# RockChip_RK3588 register map
Vendor: RockChip Electronics Co., Ltd.; Series: RK3588; File version: 0.1
Registers are 32-bit, read-write, no defined reset value unless marked. A register's access mark holds for its fields unless they carry their own. Offsets are from the block's base; [hi:lo] are bit positions; {n}, {i} and the like mark numbered series; 'fields as' and 'values as' point back to an identical list; <NAME> marks a mode.

## CRU (part 1 of 6)
Base 0xFD7C0000
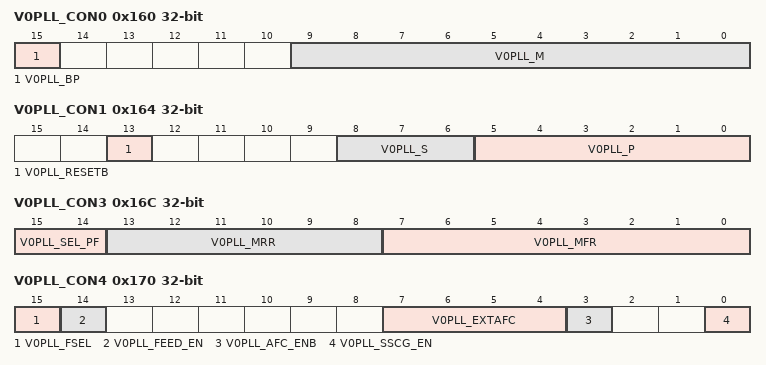
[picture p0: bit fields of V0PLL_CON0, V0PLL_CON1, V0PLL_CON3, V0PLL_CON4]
0x160 V0PLL_CON0 — V0PLL configuration register 0
  [15] V0PLL_BP — BYPASS: Bypass mode control signal.
    0=NORMAL (PLL operates normally.); 1=BYPASS (Bypass mode is enabled. (FOUT = FIN).)
  [9:0] V0PLL_M — M: Division value of the 10-bit programmable main-divider. PLL has to be reset if M value is changed. 64 <= pll_m <= 1023.
0x164 V0PLL_CON1 — V0PLL configuration register 1
  [13] V0PLL_RESETB — RESETB: Power down control signal.
    0=NORMAL (RESETB=0 from 1, PLL starts its normal operation after lock time.); 1=POWER_DOWN (RESETB=1, power down mode is enabled and all digital blocks are reset.)
  [8:6] V0PLL_S — Division value of the 3-bit programmable scaler. 0 <= pll_s <= 6.
  [5:0] V0PLL_P — P: Division value of the 6-bit programmable pre-divider. PLL has to be reset if P value is changed. 1 <= pll_p <= 63.
0x168 V0PLL_CON2 — V0PLL configuration register 2
  [15:0] V0PLL_K — K: Value of 16-bit DSM. pll_k[15:0] is a two's complement integer.
0x16C V0PLL_CON3 — V0PLL configuration register 3
  [15:14] V0PLL_SEL_PF — SEL_PF: Value of 2-bit modulation method control. PLL has to be reset if pll_sel_pf is changed.
    0=DOWN_SPREAD; 1=UP_SPREAD; 2=CENTER_SPREAD_2; 3=CENTER_SPREAD_3
  [13:8] V0PLL_MRR — MRR: Value of 6-bit modulation rate control. PLL has to be reset if pll_mrr is changed.
  [7:0] V0PLL_MFR — MFR: Value of 8-bit modulation frequency control. PLL has to be reset if pll_mfr is changed.
0x170 V0PLL_CON4 — V0PLL configuration register 4
  [15] V0PLL_FSEL — FSEL: Monitoring pin.
    0=FREF (FEED_OUT = FREF.); 1=FEED (FEED_OUT = FEED.)
  [14] V0PLL_FEED_EN — FEED_EN: Monitoring pin.
    0=DISABLED (FEED_OUT is disabled.); 1=ENABLED (FEED_OUT is enabled.)
  [7:4] V0PLL_EXTAFC — EXTAFC: Monitoring pin. If pll_afc_enb=1, AFC is disabled and VCO is calibrated manually by pll_extafc[4:0] for the test of VCO range.
  [3] V0PLL_AFC_ENB — AFC_ENB: Monitoring pin.
    0=ENABLED (AFC is enabled and VCO is calibrated automatically.); 1=DISABLED (AFC is disabled and VCO is calibrated manually by pll_extafc[4:0] for the test of VCO range.)
  [0] V0PLL_SSCG_EN — SSCG_EN: Enable pin for dithered mode.
    0=DISABLE (disable dithered mode.); 1=ENABLE (enable dithered mode.)
0x174 V0PLL_CON5 — V0PLL configuration register 5
  [0] V0PLL_FOUT_MASK — FOUT_MASK: Scaler's re-initialization time control pin.
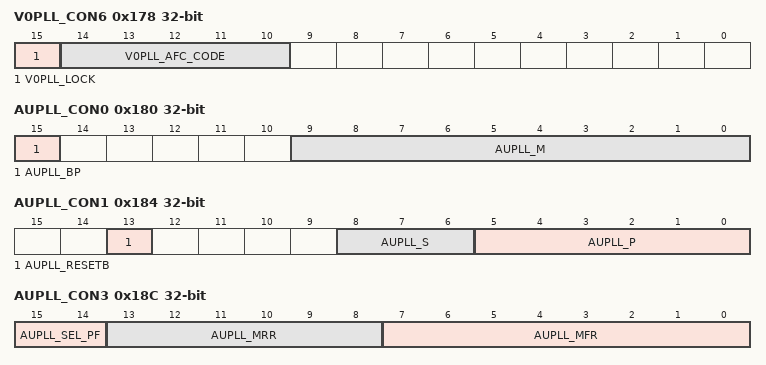
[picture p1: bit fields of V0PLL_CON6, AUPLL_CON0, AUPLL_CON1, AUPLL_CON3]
0x178 V0PLL_CON6 — V0PLL configuration register 6
  [15] V0PLL_LOCK — LOCK: PLL lock flag.
    0=UNLOCKED (PLL is unlocked.); 1=LOCKLED (PLL is locked.)
  [14:10] V0PLL_AFC_CODE — AFC_CODE: Monitoring pin. Output code of AFC(5 bits).
0x180 AUPLL_CON0 — AUPLL configuration register 0
  [15] AUPLL_BP — BYPASS: Bypass mode control signal.
    1=BYPASS (bypass mode is enabled. (FOUT = FIN).); 0=NORMAL (PLL operates normally.)
  [9:0] AUPLL_M — M: Division value of the 10-bit programmable main-divider. PLL has to be reset if M value is changed. 64 <= pll_m <= 1023.
0x184 AUPLL_CON1 — AUPLL configuration register 1
  [13] AUPLL_RESETB — RESETB: Power down control signal.
    values as V0PLL_CON1.V0PLL_RESETB
  [8:6] AUPLL_S — Division value of the 3-bit programmable scaler. 0 <= pll_s <= 6.
  [5:0] AUPLL_P — P: Division value of the 6-bit programmable pre-divider. PLL has to be reset if P value is changed. 1 <= pll_p <= 63.
0x188 AUPLL_CON2 — AUPLL configuration register 2
  [15:0] AUPLL_K — K: Value of 16-bit DSM. pll_k[15:0] is a two's complement integer.
0x18C AUPLL_CON3 — AUPLL configuration register 3
  [15:14] AUPLL_SEL_PF — SEL_PF: Value of 2-bit modulation method control. PLL has to be reset if pll_sel_pf is changed.
    values as V0PLL_CON3.V0PLL_SEL_PF
  [13:8] AUPLL_MRR — MRR: Value of 6-bit modulation rate control. PLL has to be reset if pll_mrr is changed.
  [7:0] AUPLL_MFR — MFR: Value of 8-bit modulation frequency control. PLL has to be reset if pll_mfr is changed.
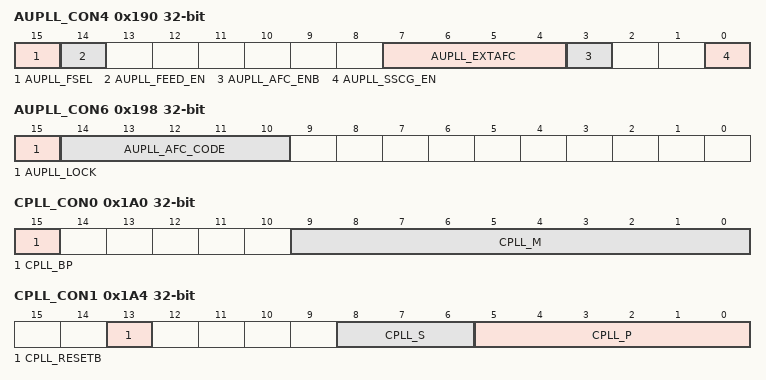
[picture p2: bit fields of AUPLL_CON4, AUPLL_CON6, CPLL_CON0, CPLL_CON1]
0x190 AUPLL_CON4 — AUPLL configuration register 4
  [15] AUPLL_FSEL — FSEL: Monitoring pin.
    0=FREF (FEED_OUT = FREF.); 1=FEED (FEED_OUT = FEED.)
  [14] AUPLL_FEED_EN — FEED_EN: Monitoring pin.
    values as V0PLL_CON4.V0PLL_FEED_EN
  [7:4] AUPLL_EXTAFC — EXTAFC: Monitoring pin. If pll_afc_enb=1, AFC is disabled and VCO is calibrated manually by pll_extafc[4:0] for the test of VCO range.
  [3] AUPLL_AFC_ENB — AFC_ENB: Monitoring pin. pll_extafc[4:0] for the test of VCO range.
    0=ENABLED (AFC is enabled and VCO is calibrated automatically.); 1=DISABLED (AFC is disabled and VCO is calibrated manually by)
  [0] AUPLL_SSCG_EN — SSCG_EN: Enable pin for dithered mode.
    values as V0PLL_CON4.V0PLL_SSCG_EN
0x194 AUPLL_CON5 — AUPLL configuration register 5
  [0] AUPLL_FOUT_MASK — FOUT_MASK: Scaler's re-initialization time control pin.
0x198 AUPLL_CON6 — AUPLL configuration register 6
  [15] AUPLL_LOCK — LOCK: PLL lock flag.
    0=UNLOCKED (PLL is unlocked.); 1=LOCKED (PLL is locked.)
  [14:10] AUPLL_AFC_CODE — AFC_CODE: Monitoring pin. Output code of AFC(5 bits).
0x1A0 CPLL_CON0 — CPLL configuration register 0
  [15] CPLL_BP — BYPASS: Bypass mode control signal.
    values as AUPLL_CON0.AUPLL_BP
  [9:0] CPLL_M — M: Division value of the 10-bit programmable main-divider. PLL has to be reset if M value is changed. 64 <= pll_m <= 1023
0x1A4 CPLL_CON1 — CPLL configuration register 1
  [13] CPLL_RESETB — RESETB: Power down control signal.
    values as V0PLL_CON1.V0PLL_RESETB
  [8:6] CPLL_S — Division value of the 3-bit programmable scaler. 0 <= pll_s <= 6
  [5:0] CPLL_P — P: Division value of the 6-bit programmable pre-divider. PLL has to be reset if P value is changed. 1 <= pll_p <= 63
0x1A8 CPLL_CON2 — CPLL configuration register 2
  [15:0] CPLL_K — K: Value of 16-bit DSM. pll_k[15:0] is a two's complement integer.
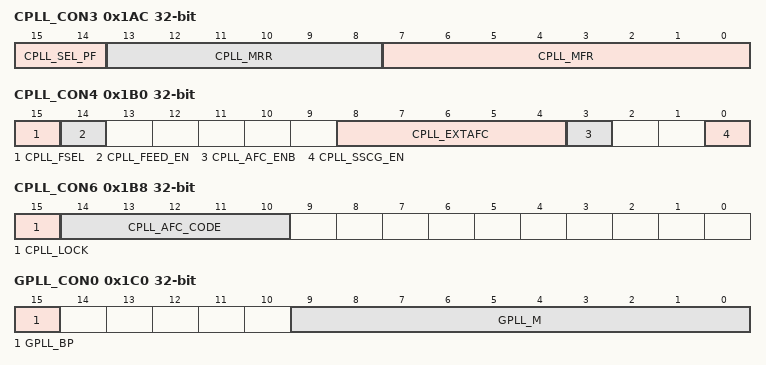
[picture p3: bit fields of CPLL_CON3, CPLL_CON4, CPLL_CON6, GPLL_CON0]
0x1AC CPLL_CON3 — CPLL configuration register 3
  [15:14] CPLL_SEL_PF — SEL_PF: Value of 2-bit modulation method control. PLL has to be reset if pll_sel_pf is changed.
    0=DOWN_SPREAD; 1=UP_SPREAD; 2=CENTER_SPREAD2; 3=CENTER_SPREAD3
  [13:8] CPLL_MRR — MRR: Value of 6-bit modulation rate control. PLL has to be reset if pll_mrr is changed.
  [7:0] CPLL_MFR — MFR: Value of 8-bit modulation frequency control. PLL has to be reset if pll_mfr is changed.
0x1B0 CPLL_CON4 — CPLL configuration register 4
  [15] CPLL_FSEL — FSEL: Monitoring pin.
    0=FREF (FEED_OUT = FREF.); 1=FEED (FEED_OUT = FEED.)
  [14] CPLL_FEED_EN — FEED_EN: Monitoring pin.
    values as V0PLL_CON4.V0PLL_FEED_EN
  [8:4] CPLL_EXTAFC — EXTAFC: Monitoring pin. If pll_afc_enb=1, AFC is disabled and VCO is calibrated manually by pll_extafc[4:0] for the test of VCO range.
  [3] CPLL_AFC_ENB — AFC_ENB: Monitoring pin.
    0=AFC is enabled and VCO is calibrated automatically; 1=AFC is disabled and VCO is calibrated manually by pll_extafc[4:0] for the test of VCO range
  [0] CPLL_SSCG_EN — SSCG_EN: Enable pin for dithered mode.
    values as V0PLL_CON4.V0PLL_SSCG_EN
0x1B4 CPLL_CON5 — CPLL configuration register 5
  [0] CPLL_FOUT_MASK — FOUT_MASK: Scaler's re-initialization time control pin.
0x1B8 CPLL_CON6 — CPLL configuration register 6
  [15] CPLL_LOCK — LOCK: PLL lock flag.
    0=UNLOCKED (PLL is unlocked.); 1=LOCKED (PLL is locked.)
  [14:10] CPLL_AFC_CODE — AFC_CODE: Monitoring pin. Output code of AFC(5 bits).
0x1C0 GPLL_CON0 — GPLL configuration register 0
  [15] GPLL_BP — BYPASS: Bypass mode control signal.
    values as AUPLL_CON0.AUPLL_BP
  [9:0] GPLL_M — M: Division value of the 10-bit programmable main-divider. PLL has to be reset if M value is changed. 64 <= pll_m <= 1023
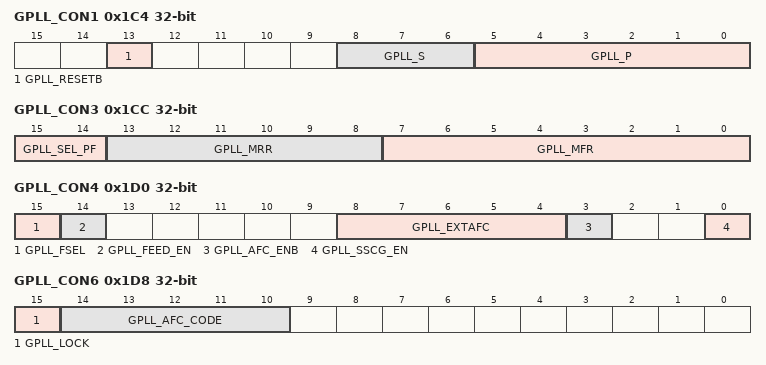
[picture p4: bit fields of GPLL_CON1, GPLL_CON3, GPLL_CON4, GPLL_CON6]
0x1C4 GPLL_CON1 — GPLL configuration register 1
  [13] GPLL_RESETB — RESETB: Power down control signal.
    values as V0PLL_CON1.V0PLL_RESETB
  [8:6] GPLL_S — Division value of the 3-bit programmable scaler. 0 <= pll_s <= 6
  [5:0] GPLL_P — P: Division value of the 6-bit programmable pre-divider. PLL has to be reset if P value is changed. 1 <= pll_p <= 63
0x1C8 GPLL_CON2 — GPLL configuration register 2
  [15:0] GPLL_K — K: Value of 16-bit DSM. pll_k[15:0] is a two's complement integer.
0x1CC GPLL_CON3 — GPLL configuration register 3
  [15:14] GPLL_SEL_PF — SEL_PF: Value of 2-bit modulation method control. PLL has to be reset if pll_sel_pf is changed.
    values as CPLL_CON3.CPLL_SEL_PF
  [13:8] GPLL_MRR — MRR: Value of 6-bit modulation rate control. PLL has to be reset if pll_mrr is changed.
  [7:0] GPLL_MFR — MFR: Value of 8-bit modulation frequency control. PLL has to be reset if pll_mfr is changed.
0x1D0 GPLL_CON4 — GPLL configuration register 4
  [15] GPLL_FSEL — FSEL: Monitoring pin.
    0=FREF (FEED_OUT = FREF.); 1=FEED (FEED_OUT = FEED.)
  [14] GPLL_FEED_EN — FEED_EN: Monitoring pin.
    values as V0PLL_CON4.V0PLL_FEED_EN
  [8:4] GPLL_EXTAFC — EXTAFC: Monitoring pin. If pll_afc_enb=1, AFC is disabled and VCO is calibrated manually by pll_extafc[4:0] for the test of VCO range.
  [3] GPLL_AFC_ENB — AFC_ENB: Monitoring pin.
    values as V0PLL_CON4.V0PLL_AFC_ENB
  [0] GPLL_SSCG_EN — SSCG_EN: Enable pin for dithered mode.
    values as V0PLL_CON4.V0PLL_SSCG_EN
0x1D4 GPLL_CON5 — GPLL configuration register 5
  [0] GPLL_FOUT_MASK — FOUT_MASK: Scaler's re-initialization time control pin.
0x1D8 GPLL_CON6 — GPLL configuration register 6
  [15] GPLL_LOCK — LOCK: PLL lock flag.
    0=UNLOCKED (PLL is unlocked.); 1=LOCKED (PLL is locked.)
  [14:10] GPLL_AFC_CODE — AFC_CODE: Monitoring pin. Output code of AFC(5 bits).
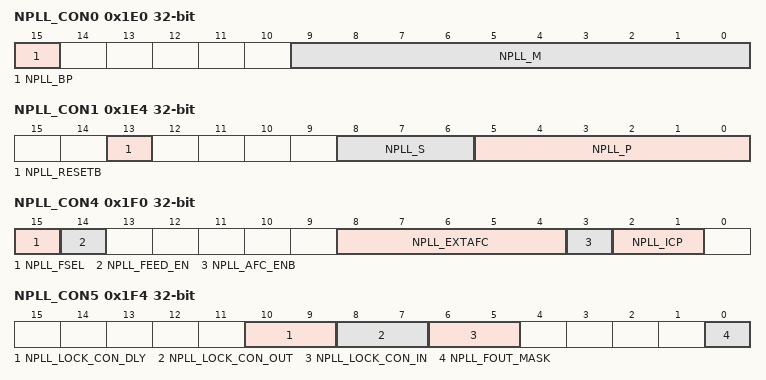
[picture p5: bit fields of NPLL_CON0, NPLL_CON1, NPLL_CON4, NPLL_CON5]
0x1E0 NPLL_CON0 — Internal PLL mode select register 0
  [15] NPLL_BP — BYPASS: Bypass mode control signal.
    values as AUPLL_CON0.AUPLL_BP
  [9:0] NPLL_M — M: Division value of the 10-bit programmable main-divider. PLL has to be reset if M value is changed. 64 <= pll_m <= 1023
0x1E4 NPLL_CON1 — Internal PLL mode select register 1
  [13] NPLL_RESETB — RESETB: Power down control signal.
    values as V0PLL_CON1.V0PLL_RESETB
  [8:6] NPLL_S — Division value of the 3-bit programmable scaler. 0 <= pll_s <= 6
  [5:0] NPLL_P — P: Division value of the 6-bit programmable pre-divider. PLL has to be reset if P value is changed. 1 <= pll_p <= 63
0x1F0 NPLL_CON4 — Internal PLL mode select register 4
  [15] NPLL_FSEL — FSEL: Monitoring pin.
    0=FREF (FEED_OUT = FREF.); 1=FEED (FEED_OUT = FEED.)
  [14] NPLL_FEED_EN — FEED_EN: Monitoring pin.
    values as V0PLL_CON4.V0PLL_FEED_EN
  [8:4] NPLL_EXTAFC — EXTAFC: Monitoring pin. If pll_afc_enb=1, AFC is disabled and VCO is calibrated manually by pll_extafc[4:0] for the test of VCO range.
  [3] NPLL_AFC_ENB — AFC_ENB: Monitoring pin.
    values as V0PLL_CON4.V0PLL_AFC_ENB
  [2:1] NPLL_ICP — Charge-pump current control signal.
0x1F4 NPLL_CON5 — Internal PLL mode select register 5
  [10:9] NPLL_LOCK_CON_DLY — LOCK_CON_DLY: Lock detector setting of the detection resolution.
  [8:7] NPLL_LOCK_CON_OUT — LOCK_CON_OUT: Lock detector setting of the output margin.
  [6:5] NPLL_LOCK_CON_IN — LOCK_CON_IN: Lock detector setting of the input margin.
  [0] NPLL_FOUT_MASK — FOUT_MASK: Scaler's re-initialization time control pin.
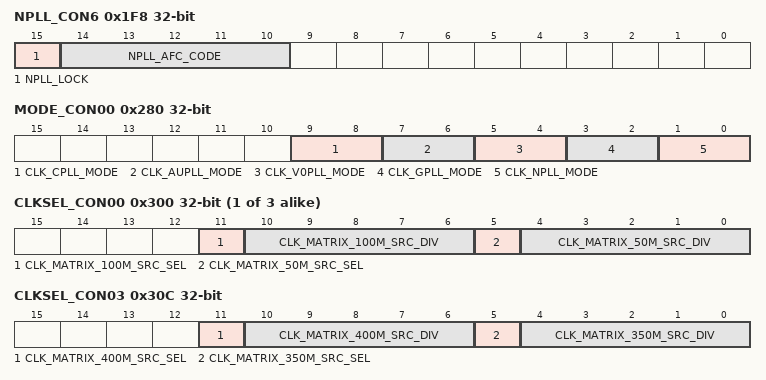
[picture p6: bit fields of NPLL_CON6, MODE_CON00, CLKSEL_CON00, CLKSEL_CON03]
0x1F8 NPLL_CON6 — Internal PLL mode select register 6
  [15] NPLL_LOCK — LOCK: PLL lock flag.
    0=UNLOCKED (PLL is unlocked.); 1=LOCKED (PLL is locked.)
  [14:10] NPLL_AFC_CODE — AFC_CODE: Monitoring pin. Output code of AFC(5 bits).
0x280 MODE_CON00 — Internal PLL mode select register
  [9:8] CLK_CPLL_MODE — clk_cpll_mux clock mux.
    0=XIN_OSC0_FUNC; 1=CLK_CPLL; 2=CLK_DEEPSLOW
  [7:6] CLK_AUPLL_MODE — clk_aupll_mux clock mux.
    0=XIN_OSC0_FUNC; 1=CLK_AUPLL; 2=CLK_DEEPSLOW
  [5:4] CLK_V0PLL_MODE — clk_v0pll_mux clock mux.
    0=XIN_OSC0_FUNC; 1=CLK_V0PLL; 2=CLK_DEEPSLOW
  [3:2] CLK_GPLL_MODE — clk_gpll_mux clock mux.
    0=XIN_OSC0_FUNC; 1=CLK_GPLL; 2=CLK_DEEPSLOW
  [1:0] CLK_NPLL_MODE — clk_npll_mux clock mux.
    0=XIN_OSC0_FUNC; 1=CLK_NPLL; 2=CLK_DEEPSLOW
{0x300+4i} CLKSEL_CON{i:02} (i=0..2) — Internal clock select and division register {i}
  [11] CLK_MATRIX_{100i+100}M_SRC_SEL — clk_matrix_{100i+100}m_src clock mux.
    0=CLK_GPLL_MUX; 1=CLK_CPLL_MUX
  [10:6] CLK_MATRIX_{100i+100}M_SRC_DIV — Divide clk_matrix_{100i+100}m_src by (div_con + 1).
  [5] CLK_MATRIX_{100i+50}M_SRC_SEL — clk_matrix_{100i+50}m_src clock mux.
    0=CLK_GPLL_MUX; 1=CLK_CPLL_MUX
  [4:0] CLK_MATRIX_{100i+50}M_SRC_DIV — Divide clk_matrix_{100i+50}m_src by (div_con + 1).
0x30C CLKSEL_CON03 — Internal clock select and division register 3
  [11] CLK_MATRIX_400M_SRC_SEL — clk_matrix_400m_src clock mux.
    0=CLK_GPLL_MUX; 1=CLK_CPLL_MUX
  [10:6] CLK_MATRIX_400M_SRC_DIV — Divide clk_matrix_400m_src by (div_con + 1).
  [5] CLK_MATRIX_350M_SRC_SEL — clk_matrix_350m_src clock mux.
    0=CLK_GPLL_MUX; 1=CLK_SPLL_MUX
  [4:0] CLK_MATRIX_350M_SRC_DIV — Divide clk_matrix_350m_src by (div_con + 1).
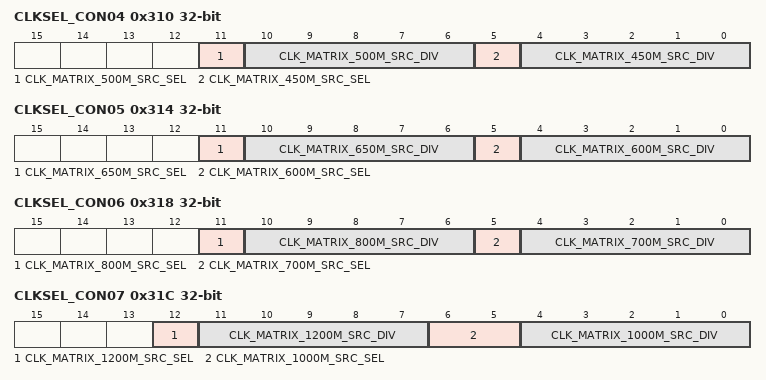
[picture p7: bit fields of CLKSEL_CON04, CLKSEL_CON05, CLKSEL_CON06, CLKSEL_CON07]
0x310 CLKSEL_CON04 — Internal clock select and division register 4
  [11] CLK_MATRIX_500M_SRC_SEL — clk_matrix_500m_src clock mux.
    0=CLK_GPLL_MUX; 1=CLK_CPLL_MUX
  [10:6] CLK_MATRIX_500M_SRC_DIV — Divide clk_matrix_500m_src by (div_con + 1).
  [5] CLK_MATRIX_450M_SRC_SEL — clk_matrix_450m_src clock mux.
    0=CLK_GPLL_MUX; 1=CLK_CPLL_MUX
  [4:0] CLK_MATRIX_450M_SRC_DIV — NP5 division register. Divide clk_matrix_450m_src by ((2 * div_con + 3) / 2).
0x314 CLKSEL_CON05 — Internal clock select and division register 5
  [11] CLK_MATRIX_650M_SRC_SEL — clk_matrix_650m_src clock mux.
    0=CLK_GPLL_MUX; 1=CLK_LPLL_MUX
  [10:6] CLK_MATRIX_650M_SRC_DIV — Divide clk_matrix_650m_src by (div_con + 1).
  [5] CLK_MATRIX_600M_SRC_SEL — clk_matrix_600m_src clock mux.
    0=CLK_GPLL_MUX; 1=CLK_CPLL_MUX
  [4:0] CLK_MATRIX_600M_SRC_DIV — Divide clk_matrix_600m_src by (div_con + 1).
0x318 CLKSEL_CON06 — Internal clock select and division register 6
  [11] CLK_MATRIX_800M_SRC_SEL — clk_matrix_800m_src clock mux.
    0=CLK_GPLL_MUX; 1=CLK_AUPLL_MUX
  [10:6] CLK_MATRIX_800M_SRC_DIV — Divide clk_matrix_800m_src by (div_con + 1).
  [5] CLK_MATRIX_700M_SRC_SEL — clk_matrix_700m_src clock mux.
    0=CLK_GPLL_MUX; 1=CLK_SPLL_MUX
  [4:0] CLK_MATRIX_700M_SRC_DIV — Divide clk_matrix_700m_src by (div_con + 1).
0x31C CLKSEL_CON07 — Internal clock select and division register 7
  [12] CLK_MATRIX_1200M_SRC_SEL — clk_matrix_1200m_src clock mux.
    0=CLK_GPLL_MUX; 1=CLK_CPLL_MUX
  [11:7] CLK_MATRIX_1200M_SRC_DIV — Divide clk_matrix_1200m_src by (div_con + 1).
  [6:5] CLK_MATRIX_1000M_SRC_SEL — clk_matrix_1000m_src clock mux.
    0=CLK_GPLL_MUX; 1=CLK_CPLL_MUX; 2=CLK_NPLL_MUX; 3=CLK_V0PLL_MUX
  [4:0] CLK_MATRIX_1000M_SRC_DIV — NP5 division register. Divide clk_matrix_1000m_src by ((2 * div_con + 3) / 2).
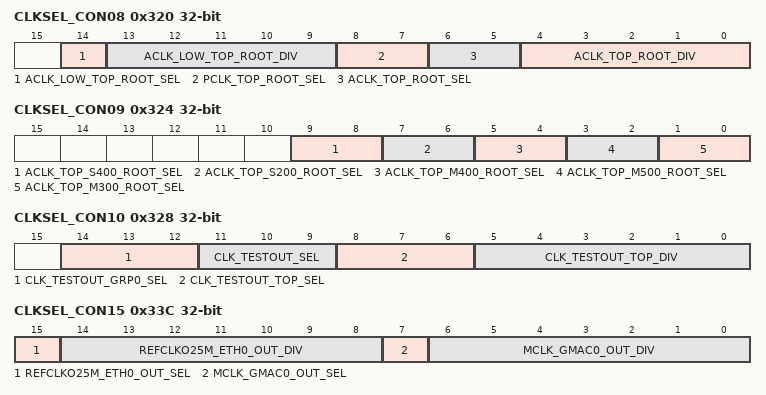
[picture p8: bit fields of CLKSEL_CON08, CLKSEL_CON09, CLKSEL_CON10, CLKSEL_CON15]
0x320 CLKSEL_CON08 — Internal clock select and division register 8
  [14] ACLK_LOW_TOP_ROOT_SEL — aclk_low_top_root clock mux.
    0=CLK_GPLL_MUX; 1=CLK_CPLL_MUX
  [13:9] ACLK_LOW_TOP_ROOT_DIV — Divide aclk_low_top_root by (div_con + 1).
  [8:7] PCLK_TOP_ROOT_SEL — pclk_top_root clock mux.
    0=CLK_MATRIX_100M_SRC; 1=CLK_MATRIX_50M_SRC; 2=XIN_OSC0_FUNC
  [6:5] ACLK_TOP_ROOT_SEL — aclk_top_root clock mux.
    0=CLK_GPLL_MUX; 1=CLK_CPLL_MUX; 2=CLK_AUPLL_MUX
  [4:0] ACLK_TOP_ROOT_DIV — Divide aclk_top_root by (div_con + 1).
0x324 CLKSEL_CON09 — Internal clock select and division register 9
  [9:8] ACLK_TOP_S400_ROOT_SEL — aclk_top_s400_root clock mux.
    0=CLK_MATRIX_400M_SRC; 1=CLK_MATRIX_200M_SRC; 2=CLK_MATRIX_100M_SRC; 3=XIN_OSC0_FUNC
  [7:6] ACLK_TOP_S200_ROOT_SEL — aclk_top_s200_root clock mux.
    0=CLK_MATRIX_200M_SRC; 1=CLK_MATRIX_100M_SRC; 2=CLK_MATRIX_50M_SRC; 3=XIN_OSC0_FUNC
  [5:4] ACLK_TOP_M400_ROOT_SEL — aclk_top_m400_root clock mux.
    values as ACLK_TOP_S400_ROOT_SEL
  [3:2] ACLK_TOP_M500_ROOT_SEL — aclk_top_m500_root clock mux.
    0=CLK_MATRIX_500M_SRC; 1=CLK_MATRIX_300M_SRC; 2=CLK_MATRIX_100M_SRC; 3=XIN_OSC0_FUNC
  [1:0] ACLK_TOP_M300_ROOT_SEL — aclk_top_m300_root clock mux.
    0=CLK_MATRIX_300M_SRC; 1=CLK_MATRIX_200M_SRC; 2=CLK_MATRIX_100M_SRC; 3=XIN_OSC0_FUNC
0x328 CLKSEL_CON10 — Internal clock select and division register 10
  [14:12] CLK_TESTOUT_GRP0_SEL — clk_testout_grp0 clock mux.
    0=CLK_REF_PIPE_PHY0; 1=CLK_REF_PIPE_PHY1; 2=CLK_REF_PIPE_PHY2; 3=CLK_TESTOUT_TOP; 4=CLK_TESTOUT_GPU; 5=CLK_TESTOUT_NPU
  [11:9] CLK_TESTOUT_SEL — clk_testout clock mux.
    0=CLK_TESTOUT_GRP0; 1=CLK_TESTOUT_B0; 2=CLK_TESTOUT_B1; 3=CLK_TESTOUT_L; 4=CLK_TESTOUT_DDR01; 5=CLK_TESTOUT_DDR23
  [8:6] CLK_TESTOUT_TOP_SEL — clk_testout_top clock mux.
    0=CLK_GPLL_MUX; 1=CLK_CPLL_MUX; 2=CLK_AUPLL_MUX; 3=CLK_SPLL_MUX; 4=CLK_V0PLL_MUX; 5=CLK_DEEPSLOW
  [5:0] CLK_TESTOUT_TOP_DIV — Divide clk_testout_top by (div_con + 1).
0x33C CLKSEL_CON15 — Internal clock select and division register 15
  [15] REFCLKO25M_ETH0_OUT_SEL — refclko25m_eth0_out clock mux.
    0=CLK_GPLL_MUX; 1=CLK_CPLL_MUX
  [14:8] REFCLKO25M_ETH0_OUT_DIV — Divide refclko25m_eth0_out by (div_con + 1).
  [7] MCLK_GMAC0_OUT_SEL — mclk_gmac0_out clock mux.
    0=CLK_GPLL_MUX; 1=CLK_CPLL_MUX
  [6:0] MCLK_GMAC0_OUT_DIV — Divide mclk_gmac0_out by (div_con + 1).
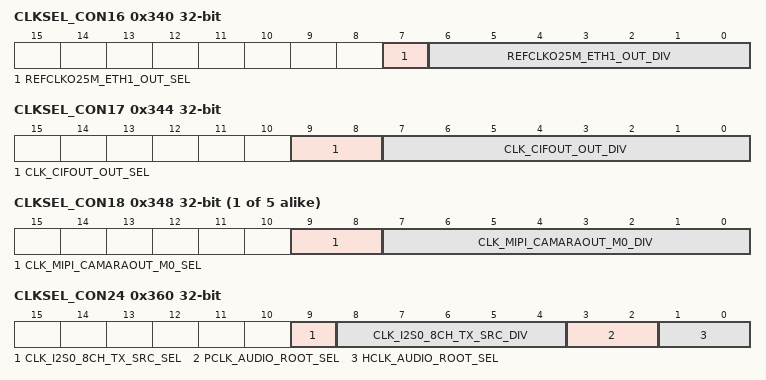
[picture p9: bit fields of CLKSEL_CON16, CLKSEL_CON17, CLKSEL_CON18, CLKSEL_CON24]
0x340 CLKSEL_CON16 — Internal clock select and division register 16
  [7] REFCLKO25M_ETH1_OUT_SEL — refclko25m_eth1_out clock mux.
    0=CLK_GPLL_MUX; 1=CLK_CPLL_MUX
  [6:0] REFCLKO25M_ETH1_OUT_DIV — Divide refclko25m_eth1_out by (div_con + 1).
0x344 CLKSEL_CON17 — Internal clock select and division register 17
  [9:8] CLK_CIFOUT_OUT_SEL — clk_cifout_out clock mux.
    0=CLK_GPLL_MUX; 1=CLK_CPLL_MUX; 2=XIN_OSC0_FUNC; 3=CLK_SPLL_MUX
  [7:0] CLK_CIFOUT_OUT_DIV — Divide clk_cifout_out by (div_con + 1).
{0x300+4i} CLKSEL_CON{i} (i=18..22) — Internal clock select and division register {i}
  [9:8] CLK_MIPI_CAMARAOUT_M{i-18}_SEL — clk_mipi_camaraout_m{i-18} clock mux.
    0=XIN_OSC0_FUNC; 1=CLK_SPLL_MUX; 2=CLK_GPLL_MUX; 3=CLK_CPLL_MUX
  [7:0] CLK_MIPI_CAMARAOUT_M{i-18}_DIV — Divide clk_mipi_camaraout_m{i-18} by (div_con + 1).
0x360 CLKSEL_CON24 — Internal clock select and division register 24
  [9] CLK_I2S0_8CH_TX_SRC_SEL — clk_i2s0_8ch_tx_src clock mux.
    0=CLK_GPLL_MUX; 1=CLK_AUPLL_MUX
  [8:4] CLK_I2S0_8CH_TX_SRC_DIV — Divide clk_i2s0_8ch_tx_src by (div_con + 1).
  [3:2] PCLK_AUDIO_ROOT_SEL — pclk_audio_root clock mux.
    0=CLK_MATRIX_100M_SRC; 1=CLK_MATRIX_50M_SRC; 2=XIN_OSC0_FUNC
  [1:0] HCLK_AUDIO_ROOT_SEL — hclk_audio_root clock mux.
    values as CLKSEL_CON09.ACLK_TOP_S200_ROOT_SEL
0x364 CLKSEL_CON25 — Internal clock select and division register 25
  [31:0] CLK_I2S0_8CH_TX_FRAC_DIV — clk_i2s0_8ch_tx_frac fraction division register. High 16-bit for numerator Low 16-bit for denominator
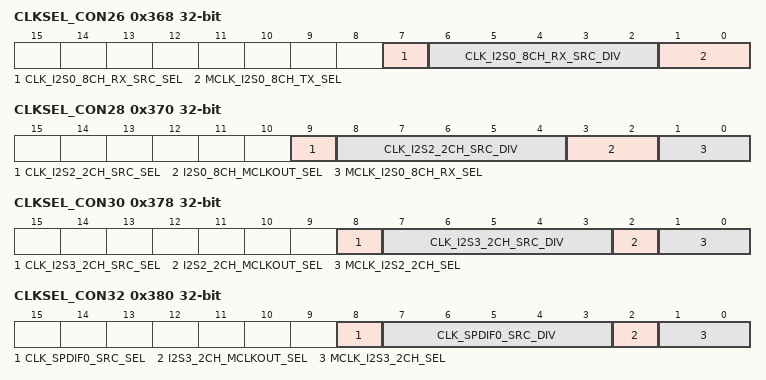
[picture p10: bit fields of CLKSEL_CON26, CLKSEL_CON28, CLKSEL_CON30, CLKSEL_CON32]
0x368 CLKSEL_CON26 — Internal clock select and division register 26
  [7] CLK_I2S0_8CH_RX_SRC_SEL — clk_i2s0_8ch_rx_src clock mux.
    0=CLK_GPLL_MUX; 1=CLK_AUPLL_MUX
  [6:2] CLK_I2S0_8CH_RX_SRC_DIV — Divide clk_i2s0_8ch_rx_src by (div_con + 1).
  [1:0] MCLK_I2S0_8CH_TX_SEL — mclk_i2s0_8ch_tx clock mux.
    0=CLK_I2S0_8CH_TX_SRC; 1=CLK_I2S0_8CH_TX_FRAC; 2=I2S0_MCLKIN; 3=XIN_OSC0_HALF
0x36C CLKSEL_CON27 — Internal clock select and division register 27
  [31:0] CLK_I2S0_8CH_RX_FRAC_DIV — clk_i2s0_8ch_rx_frac fraction division register. High 16-bit for numerator Low 16-bit for denominator
0x370 CLKSEL_CON28 — Internal clock select and division register 28
  [9] CLK_I2S2_2CH_SRC_SEL — clk_i2s2_2ch_src clock mux.
    0=CLK_GPLL_MUX; 1=CLK_AUPLL_MUX
  [8:4] CLK_I2S2_2CH_SRC_DIV — Divide clk_i2s2_2ch_src by (div_con + 1).
  [3:2] I2S0_8CH_MCLKOUT_SEL — i2s0_8ch_mclkout clock mux.
    0=MCLK_I2S0_8CH_TX; 1=MCLK_I2S0_8CH_RX; 2=XIN_OSC0_HALF
  [1:0] MCLK_I2S0_8CH_RX_SEL — mclk_i2s0_8ch_rx clock mux.
    0=CLK_I2S0_8CH_RX_SRC; 1=CLK_I2S0_8CH_RX_FRAC; 2=I2S0_MCLKIN; 3=XIN_OSC0_HALF
0x374 CLKSEL_CON29 — Internal clock select and division register 29
  [31:0] CLK_I2S2_2CH_FRAC_DIV — clk_i2s2_2ch_frac fraction division register. High 16-bit for numerator Low 16-bit for denominator
0x378 CLKSEL_CON30 — Internal clock select and division register 30
  [8] CLK_I2S3_2CH_SRC_SEL — clk_i2s3_2ch_src clock mux.
    0=CLK_GPLL_MUX; 1=CLK_AUPLL_MUX
  [7:3] CLK_I2S3_2CH_SRC_DIV — Divide clk_i2s3_2ch_src by (div_con + 1).
  [2] I2S2_2CH_MCLKOUT_SEL — i2s2_2ch_mclkout clock mux.
    0=MCLK_I2S2_2CH; 1=XIN_OSC0_HALF
  [1:0] MCLK_I2S2_2CH_SEL — mclk_i2s2_2ch clock mux.
    0=CLK_I2S2_2CH_SRC; 1=CLK_I2S2_2CH_FRAC; 2=I2S2_MCLKIN; 3=XIN_OSC0_HALF
0x37C CLKSEL_CON31 — Internal clock select and division register 31
  [31:0] CLK_I2S3_2CH_FRAC_DIV — clk_i2s3_2ch_frac fraction division register. High 16-bit for numerator Low 16-bit for denominator
0x380 CLKSEL_CON32 — Internal clock select and division register 32
  [8] CLK_SPDIF0_SRC_SEL — clk_spdif0_src clock mux.
    0=CLK_GPLL_MUX; 1=CLK_AUPLL_MUX
  [7:3] CLK_SPDIF0_SRC_DIV — Divide clk_spdif0_src by (div_con + 1).
  [2] I2S3_2CH_MCLKOUT_SEL — i2s3_2ch_mclkout clock mux.
    0=MCLK_I2S3_2CH; 1=XIN_OSC0_HALF
  [1:0] MCLK_I2S3_2CH_SEL — mclk_i2s3_2ch clock mux.
    0=CLK_I2S3_2CH_SRC; 1=CLK_I2S3_2CH_FRAC; 2=I2S3_MCLKIN; 3=XIN_OSC0_HALF
0x384 CLKSEL_CON33 — Internal clock select and division register 33
  [31:0] CLK_SPDIF0_FRAC_DIV — clk_spdif0_frac fraction division register. High 16-bit for numerator Low 16-bit for denominator
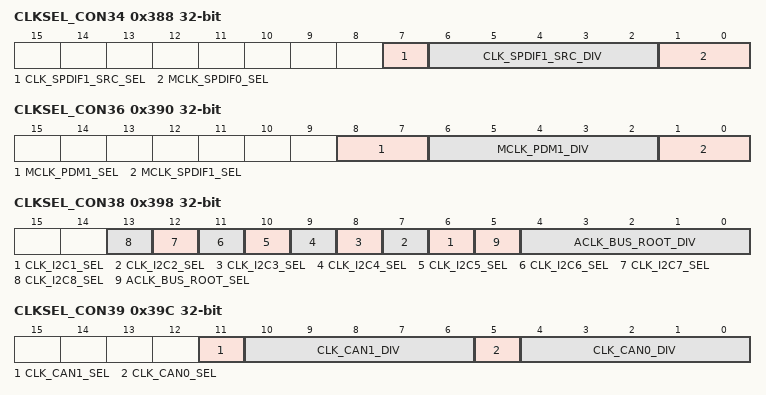
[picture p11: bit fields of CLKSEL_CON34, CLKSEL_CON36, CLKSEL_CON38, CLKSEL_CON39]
0x388 CLKSEL_CON34 — Internal clock select and division register 34
  [7] CLK_SPDIF1_SRC_SEL — clk_spdif1_src clock mux.
    0=CLK_GPLL_MUX; 1=CLK_AUPLL_MUX
  [6:2] CLK_SPDIF1_SRC_DIV — Divide clk_spdif1_src by (div_con + 1).
  [1:0] MCLK_SPDIF0_SEL — mclk_spdif0 clock mux.
    0=CLK_SPDIF0_SRC; 1=CLK_SPDIF0_FRAC; 2=XIN_OSC0_HALF
0x38C CLKSEL_CON35 — Internal clock select and division register 35
  [31:0] CLK_SPDIF1_FRAC_DIV — clk_spdif1_frac fraction division register. High 16-bit for numerator Low 16-bit for denominator
0x390 CLKSEL_CON36 — Internal clock select and division register 36
  [8:7] MCLK_PDM1_SEL — mclk_pdm1 clock mux.
    0=CLK_GPLL_MUX; 1=CLK_CPLL_MUX; 2=CLK_AUPLL_MUX
  [6:2] MCLK_PDM1_DIV — Divide mclk_pdm1 by (div_con + 1).
  [1:0] MCLK_SPDIF1_SEL — mclk_spdif1 clock mux.
    0=CLK_SPDIF1_SRC; 1=CLK_SPDIF1_FRAC; 2=XIN_OSC0_HALF
0x398 CLKSEL_CON38 — Internal clock select and division register 38
  [n+5] CLK_I2C{n}_SEL (n=1..8) — clk_i2c{n} clock mux.
    0=CLK_MATRIX_200M_SRC; 1=CLK_MATRIX_100M_SRC
  [5] ACLK_BUS_ROOT_SEL — aclk_bus_root clock mux.
    0=CLK_GPLL_MUX; 1=CLK_CPLL_MUX
  [4:0] ACLK_BUS_ROOT_DIV — Divide aclk_bus_root by (div_con + 1).
0x39C CLKSEL_CON39 — Internal clock select and division register 39
  [11] CLK_CAN1_SEL — clk_can1 clock mux.
    0=CLK_GPLL_MUX; 1=CLK_CPLL_MUX
  [10:6] CLK_CAN1_DIV — Divide clk_can1 by (div_con + 1).
  [5] CLK_CAN0_SEL — clk_can0 clock mux.
    0=CLK_GPLL_MUX; 1=CLK_CPLL_MUX
  [4:0] CLK_CAN0_DIV — Divide clk_can0 by (div_con + 1).
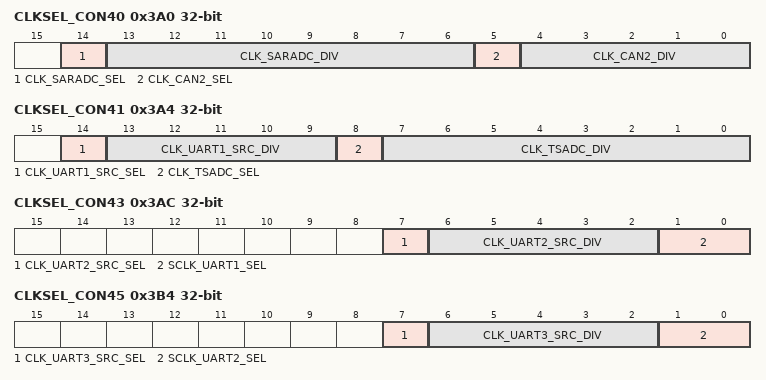
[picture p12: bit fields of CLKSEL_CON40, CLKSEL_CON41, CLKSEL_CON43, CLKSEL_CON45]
0x3A0 CLKSEL_CON40 — Internal clock select and division register 40
  [14] CLK_SARADC_SEL — clk_saradc clock mux.
    0=CLK_GPLL_MUX; 1=XIN_OSC0_FUNC
  [13:6] CLK_SARADC_DIV — Divide clk_saradc by (div_con + 1).
  [5] CLK_CAN2_SEL — clk_can2 clock mux.
    0=CLK_GPLL_MUX; 1=CLK_CPLL_MUX
  [4:0] CLK_CAN2_DIV — Divide clk_can2 by (div_con + 1).
0x3A4 CLKSEL_CON41 — Internal clock select and division register 41
  [14] CLK_UART1_SRC_SEL — clk_uart1_src clock mux.
    0=CLK_GPLL_MUX; 1=CLK_CPLL_MUX
  [13:9] CLK_UART1_SRC_DIV — Divide clk_uart1_src by (div_con + 1).
  [8] CLK_TSADC_SEL — clk_tsadc clock mux.
    0=CLK_GPLL_MUX; 1=XIN_OSC0_FUNC
  [7:0] CLK_TSADC_DIV — Divide clk_tsadc by (div_con + 1).
0x3A8 CLKSEL_CON42 — Internal clock select and division register 42
  [31:0] CLK_UART1_FRAC_DIV — clk_uart1_frac fraction division register. High 16-bit for numerator Low 16-bit for denominator
0x3AC CLKSEL_CON43 — Internal clock select and division register 43
  [7] CLK_UART2_SRC_SEL — clk_uart2_src clock mux.
    0=CLK_GPLL_MUX; 1=CLK_CPLL_MUX
  [6:2] CLK_UART2_SRC_DIV — Divide clk_uart2_src by (div_con + 1).
  [1:0] SCLK_UART1_SEL — sclk_uart1 clock mux.
    0=CLK_UART1_SRC; 1=CLK_UART1_FRAC; 2=XIN_OSC0_FUNC
0x3B0 CLKSEL_CON44 — Internal clock select and division register 44
  [31:0] CLK_UART2_FRAC_DIV — clk_uart2_frac fraction division register. High 16-bit for numerator Low 16-bit for denominator
0x3B4 CLKSEL_CON45 — Internal clock select and division register 45
  [7] CLK_UART3_SRC_SEL — clk_uart3_src clock mux.
    0=CLK_GPLL_MUX; 1=CLK_CPLL_MUX
  [6:2] CLK_UART3_SRC_DIV — Divide clk_uart3_src by (div_con + 1).
  [1:0] SCLK_UART2_SEL — sclk_uart2 clock mux.
    0=CLK_UART2_SRC; 1=CLK_UART2_FRAC; 2=XIN_OSC0_FUNC
0x3B8 CLKSEL_CON46 — Internal clock select and division register 46
  [31:0] CLK_UART3_FRAC_DIV — clk_uart3_frac fraction division register. High 16-bit for numerator Low 16-bit for denominator
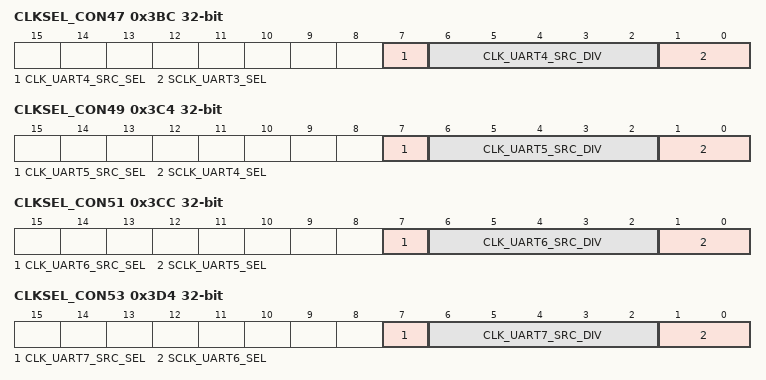
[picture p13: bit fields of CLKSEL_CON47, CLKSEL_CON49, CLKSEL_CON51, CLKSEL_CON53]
0x3BC CLKSEL_CON47 — Internal clock select and division register 47
  [7] CLK_UART4_SRC_SEL — clk_uart4_src clock mux.
    0=CLK_GPLL_MUX; 1=CLK_CPLL_MUX
  [6:2] CLK_UART4_SRC_DIV — Divide clk_uart4_src by (div_con + 1).
  [1:0] SCLK_UART3_SEL — sclk_uart3 clock mux.
    0=CLK_UART3_SRC; 1=CLK_UART3_FRAC; 2=XIN_OSC0_FUNC
0x3C0 CLKSEL_CON48 — Internal clock select and division register 48
  [31:0] CLK_UART4_FRAC_DIV — clk_uart4_frac fraction division register. High 16-bit for numerator Low 16-bit for denominator
0x3C4 CLKSEL_CON49 — Internal clock select and division register 49
  [7] CLK_UART5_SRC_SEL — clk_uart5_src clock mux.
    0=CLK_GPLL_MUX; 1=CLK_CPLL_MUX
  [6:2] CLK_UART5_SRC_DIV — Divide clk_uart5_src by (div_con + 1).
  [1:0] SCLK_UART4_SEL — sclk_uart4 clock mux.
    0=CLK_UART4_SRC; 1=CLK_UART4_FRAC; 2=XIN_OSC0_FUNC
0x3C8 CLKSEL_CON50 — Internal clock select and division register 50
  [31:0] CLK_UART5_FRAC_DIV — clk_uart5_frac fraction division register. High 16-bit for numerator Low 16-bit for denominator
0x3CC CLKSEL_CON51 — Internal clock select and division register 51
  [7] CLK_UART6_SRC_SEL — clk_uart6_src clock mux.
    0=CLK_GPLL_MUX; 1=CLK_CPLL_MUX
  [6:2] CLK_UART6_SRC_DIV — Divide clk_uart6_src by (div_con + 1).
  [1:0] SCLK_UART5_SEL — sclk_uart5 clock mux.
    0=CLK_UART5_SRC; 1=CLK_UART5_FRAC; 2=XIN_OSC0_FUNC
0x3D0 CLKSEL_CON52 — Internal clock select and division register 52
  [31:0] CLK_UART6_FRAC_DIV — clk_uart6_frac fraction division register. High 16-bit for numerator Low 16-bit for denominator
0x3D4 CLKSEL_CON53 — Internal clock select and division register 53
  [7] CLK_UART7_SRC_SEL — clk_uart7_src clock mux.
    0=CLK_GPLL_MUX; 1=CLK_CPLL_MUX
  [6:2] CLK_UART7_SRC_DIV — Divide clk_uart7_src by (div_con + 1).
  [1:0] SCLK_UART6_SEL — sclk_uart6 clock mux.
    0=CLK_UART6_SRC; 1=CLK_UART6_FRAC; 2=XIN_OSC0_FUNC
0x3D8 CLKSEL_CON54 — Internal clock select and division register 54
  [31:0] CLK_UART7_FRAC_DIV — clk_uart7_frac fraction division register. High 16-bit for numerator Low 16-bit for denominator
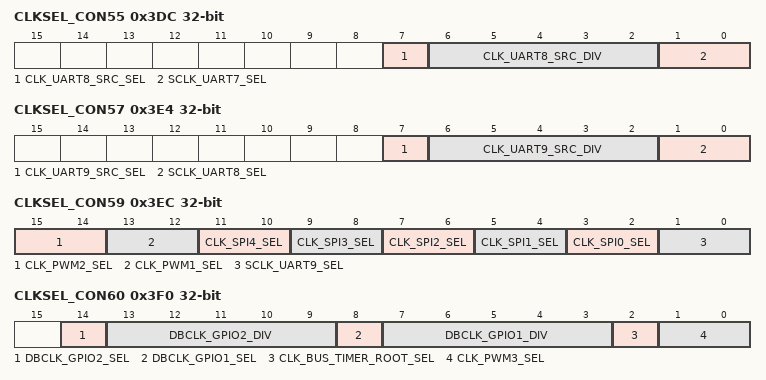
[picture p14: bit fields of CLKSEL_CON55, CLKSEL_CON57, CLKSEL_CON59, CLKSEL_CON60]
0x3DC CLKSEL_CON55 — Internal clock select and division register 55
  [7] CLK_UART8_SRC_SEL — clk_uart8_src clock mux.
    0=CLK_GPLL_MUX; 1=CLK_CPLL_MUX
  [6:2] CLK_UART8_SRC_DIV — Divide clk_uart8_src by (div_con + 1).
  [1:0] SCLK_UART7_SEL — sclk_uart7 clock mux.
    0=CLK_UART7_SRC; 1=CLK_UART7_FRAC; 2=XIN_OSC0_FUNC
0x3E0 CLKSEL_CON56 — Internal clock select and division register 56
  [31:0] CLK_UART8_FRAC_DIV — clk_uart8_frac fraction division register. High 16-bit for numerator Low 16-bit for denominator
0x3E4 CLKSEL_CON57 — Internal clock select and division register 57
  [7] CLK_UART9_SRC_SEL — clk_uart9_src clock mux.
    0=CLK_GPLL_MUX; 1=CLK_CPLL_MUX
  [6:2] CLK_UART9_SRC_DIV — Divide clk_uart9_src by (div_con + 1).
  [1:0] SCLK_UART8_SEL — sclk_uart8 clock mux.
    0=CLK_UART8_SRC; 1=CLK_UART8_FRAC; 2=XIN_OSC0_FUNC
0x3E8 CLKSEL_CON58 — Internal clock select and division register 58
  [31:0] CLK_UART9_FRAC_DIV — clk_uart9_frac fraction division register. High 16-bit for numerator Low 16-bit for denominator
0x3EC CLKSEL_CON59 — Internal clock select and division register 59
  [15:14] CLK_PWM2_SEL — clk_pwm2 clock mux.
    0=CLK_MATRIX_100M_SRC; 1=CLK_MATRIX_50M_SRC; 2=XIN_OSC0_FUNC
  [13:12] CLK_PWM1_SEL — clk_pwm1 clock mux.
    0=CLK_MATRIX_100M_SRC; 1=CLK_MATRIX_50M_SRC; 2=XIN_OSC0_FUNC
  [2n+3:2n+2] CLK_SPI{n}_SEL (n=0..4) — clk_spi{n} clock mux.
    0=CLK_MATRIX_200M_SRC; 1=CLK_MATRIX_150M_SRC; 2=XIN_OSC0_FUNC
  [1:0] SCLK_UART9_SEL — sclk_uart9 clock mux.
    0=CLK_UART9_SRC; 1=CLK_UART9_FRAC; 2=XIN_OSC0_FUNC
0x3F0 CLKSEL_CON60 — Internal clock select and division register 60
  [14] DBCLK_GPIO2_SEL — dbclk_gpio2 clock mux.
    0=XIN_OSC0_FUNC; 1=CLK_DEEPSLOW
  [13:9] DBCLK_GPIO2_DIV — Divide dbclk_gpio2 by (div_con + 1).
  [8] DBCLK_GPIO1_SEL — dbclk_gpio1 clock mux.
    0=XIN_OSC0_FUNC; 1=CLK_DEEPSLOW
  [7:3] DBCLK_GPIO1_DIV — Divide dbclk_gpio1 by (div_con + 1).
  [2] CLK_BUS_TIMER_ROOT_SEL — clk_bus_timer_root clock mux.
    0=XIN_OSC0_FUNC; 1=CLK_MATRIX_100M_SRC
  [1:0] CLK_PWM3_SEL — clk_pwm3 clock mux.
    0=CLK_MATRIX_100M_SRC; 1=CLK_MATRIX_50M_SRC; 2=XIN_OSC0_FUNC
0x3F4 CLKSEL_CON61 — Internal clock select and division register 61
  [11] DBCLK_GPIO4_SEL — dbclk_gpio4 clock mux.
    0=XIN_OSC0_FUNC; 1=CLK_DEEPSLOW
  [10:6] DBCLK_GPIO4_DIV — Divide dbclk_gpio4 by (div_con + 1).
  [5] DBCLK_GPIO3_SEL — dbclk_gpio3 clock mux.
    0=XIN_OSC0_FUNC; 1=CLK_DEEPSLOW
  [4:0] DBCLK_GPIO3_DIV — Divide dbclk_gpio3 by (div_con + 1).
0x3F8 CLKSEL_CON62 — Internal clock select and division register 62
  [10:6] CLK_BISRINTF_PLLSRC_DIV — Divide clk_bisrintf_pllsrc by (div_con + 1).
  [5] DCLK_DECOM_SEL — dclk_decom clock mux.
    0=CLK_GPLL_MUX; 1=CLK_SPLL_MUX
  [4:0] DCLK_DECOM_DIV — Divide dclk_decom by (div_con + 1).
0x3FC CLKSEL_CON63 — Internal clock select and division register 63
  [6] CLK_TESTOUT_DDR01_SEL — clk_testout_ddr01 clock mux.
    0=CLK_DFI_CH0; 1=CLK_DFI_CH1
  [5:0] CLK_TESTOUT_DDR01_DIV — Divide clk_testout_ddr01 by (div_con + 1).
0x404 CLKSEL_CON65 — Internal clock select and division register 65
  [6] CLK_TESTOUT_DDR23_SEL — clk_testout_ddr23 clock mux.
    0=CLK_DFI_CH2; 1=CLK_DFI_CH3
  [5:0] CLK_TESTOUT_DDR23_DIV — Divide clk_testout_ddr23 by (div_con + 1).
0x40C CLKSEL_CON67 — Internal clock select and division register 67
  [15:14] CLK_ISP1_CORE_SEL — clk_isp1_core clock mux.
    0=CLK_GPLL_MUX; 1=CLK_CPLL_MUX; 2=CLK_AUPLL_MUX; 3=CLK_SPLL_MUX
  [13:9] CLK_ISP1_CORE_DIV — Divide clk_isp1_core by (div_con + 1).
  [8:7] HCLK_ISP1_ROOT_SEL — hclk_isp1_root clock mux.
    values as CLKSEL_CON09.ACLK_TOP_S200_ROOT_SEL
  [6:5] ACLK_ISP1_ROOT_SEL — aclk_isp1_root clock mux.
    values as CLK_ISP1_CORE_SEL
  [4:0] ACLK_ISP1_ROOT_DIV — Divide aclk_isp1_root by (div_con + 1).
0x424 CLKSEL_CON73 — Internal clock select and division register 73
  [15] CLK_TESTOUT_NPU_SEL — clk_testout_npu clock mux.
    0=CLK_RKNN_DSU0_SRC_T; 1=CLK_NPU_PVTPLL
  [14:10] CLK_TESTOUT_NPU_DIV — Divide clk_testout_npu by (div_con + 1).
  [9:7] CLK_RKNN_DSU0_SRC_T_SEL — clk_rknn_dsu0_src_t clock mux.
    0=CLK_GPLL_MUX; 1=CLK_CPLL_MUX; 2=CLK_AUPLL_MUX; 3=CLK_NPLL_MUX; 4=CLK_SPLL_MUX
  [6:2] CLK_RKNN_DSU0_SRC_T_DIV — Divide clk_rknn_dsu0_src_t by (div_con + 1).
  [1:0] HCLK_RKNN_ROOT_SEL — hclk_rknn_root clock mux.
    values as CLKSEL_CON09.ACLK_TOP_S200_ROOT_SEL
0x428 CLKSEL_CON74 — Internal clock select and division register 74
  [12] CLK_NPU_CM0_RTC_SEL — clk_npu_cm0_rtc clock mux.
    0=XIN_OSC0_FUNC; 1=CLK_DEEPSLOW
  [11:7] CLK_NPU_CM0_RTC_DIV — Divide clk_npu_cm0_rtc by (div_con + 1).
  [6:5] HCLK_NPU_CM0_ROOT_SEL — hclk_npu_cm0_root clock mux.
    values as CLKSEL_CON09.ACLK_TOP_S400_ROOT_SEL
  [4] CLK_NPU_PVTPLL_SEL — clk_npu_pvtpll clock mux.
    0=CLK_RKNN_DSU0_SRC_T; 1=XIN_OSC0_FUNC
  [3] CLK_NPUTIMER_ROOT_SEL — clk_nputimer_root clock mux.
    0=XIN_OSC0_FUNC; 1=CLK_MATRIX_100M_SRC
  [2:1] PCLK_NPUTOP_ROOT_SEL — pclk_nputop_root clock mux.
    0=CLK_MATRIX_100M_SRC; 1=CLK_MATRIX_50M_SRC; 2=XIN_OSC0_FUNC
  [0] CLK_RKNN_DSU0_SEL — clk_rknn_dsu0 clock mux.
    0=CLK_RKNN_DSU0_SRC_T; 1=CLK_NPU_PVTPLL
0x434 CLKSEL_CON77 — Internal clock select and division register 77
  [15:14] CCLK_EMMC_SEL — cclk_emmc clock mux.
    0=CLK_GPLL_MUX; 1=CLK_CPLL_MUX; 2=XIN_OSC0_FUNC
  [13:8] CCLK_EMMC_DIV — DT50 division register. Divide cclk_emmc by (div_con + 1).
  [7] ACLK_NVM_ROOT_SEL — aclk_nvm_root clock mux.
    0=CLK_GPLL_MUX; 1=CLK_CPLL_MUX
  [6:2] ACLK_NVM_ROOT_DIV — Divide aclk_nvm_root by (div_con + 1).
  [1:0] HCLK_NVM_ROOT_SEL — hclk_nvm_root clock mux.
    values as CLKSEL_CON09.ACLK_TOP_S200_ROOT_SEL
0x438 CLKSEL_CON78 — Internal clock select and division register 78
  [13:12] SCLK_SFC_SEL — sclk_sfc clock mux.
    0=CLK_GPLL_MUX; 1=CLK_CPLL_MUX; 2=XIN_OSC0_FUNC
  [11:6] SCLK_SFC_DIV — Divide sclk_sfc by (div_con + 1).
  [5] BCLK_EMMC_SEL — bclk_emmc clock mux.
    0=CLK_GPLL_MUX; 1=CLK_CPLL_MUX
  [4:0] BCLK_EMMC_DIV — Divide bclk_emmc by (div_con + 1).
0x440 CLKSEL_CON80 — Internal clock select and division register 80
  [13] ACLK_PHP_ROOT_SEL — aclk_php_root clock mux.
    0=CLK_GPLL_MUX; 1=CLK_CPLL_MUX
  [12:8] ACLK_PHP_ROOT_DIV — Divide aclk_php_root by (div_con + 1).
  [7] ACLK_PCIE_ROOT_SEL — aclk_pcie_root clock mux.
    0=CLK_GPLL_MUX; 1=CLK_CPLL_MUX
  [6:2] ACLK_PCIE_ROOT_DIV — Divide aclk_pcie_root by (div_con + 1).
  [1:0] PCLK_PHP_ROOT_SEL — pclk_php_root clock mux.
    0=CLK_MATRIX_150M_SRC; 1=CLK_MATRIX_50M_SRC; 2=XIN_OSC0_FUNC
0x444 CLKSEL_CON81 — Internal clock select and division register 81
  [13] CLK_GMAC1_PTP_REF_SEL — clk_gmac1_ptp_ref clock mux.
    0=CLK_CPLL_MUX; 1=CLK_GMAC1_PTPREFO
  [12:7] CLK_GMAC1_PTP_REF_DIV — Divide clk_gmac1_ptp_ref by (div_con + 1).
  [6] CLK_GMAC0_PTP_REF_SEL — clk_gmac0_ptp_ref clock mux.
    0=CLK_CPLL_MUX; 1=CLK_GMAC0_PTPREFO
  [5:0] CLK_GMAC0_PTP_REF_DIV — Divide clk_gmac0_ptp_ref by (div_con + 1).
0x448 CLKSEL_CON82 — Internal clock select and division register 82
  [15] CLK_RXOOB1_SEL — clk_rxoob1 clock mux.
    0=CLK_GPLL_MUX; 1=CLK_CPLL_MUX
  [14:8] CLK_RXOOB1_DIV — Divide clk_rxoob1 by (div_con + 1).
  [7] CLK_RXOOB0_SEL — clk_rxoob0 clock mux.
    0=CLK_GPLL_MUX; 1=CLK_CPLL_MUX
  [6:0] CLK_RXOOB0_DIV — Divide clk_rxoob0 by (div_con + 1).
0x44C CLKSEL_CON83 — Internal clock select and division register 83
  [15] CLK_GMAC_125M_CRU_I_SEL — clk_gmac_125m_cru_i clock mux.
    0=CLK_GPLL_MUX; 1=CLK_CPLL_MUX
  [14:8] CLK_GMAC_125M_CRU_I_DIV — Divide clk_gmac_125m_cru_i by (div_con + 1).
  [7] CLK_RXOOB2_SEL — clk_rxoob2 clock mux.
    0=CLK_GPLL_MUX; 1=CLK_CPLL_MUX
  [6:0] CLK_RXOOB2_DIV — Divide clk_rxoob2 by (div_con + 1).
0x450 CLKSEL_CON84 — Internal clock select and division register 84
  [13:12] CLK_UTMI_OTG2_SEL — clk_utmi_otg2 clock mux.
    0=CLK_MATRIX_150M_SRC; 1=CLK_MATRIX_50M_SRC; 2=XIN_OSC0_FUNC
  [11:8] CLK_UTMI_OTG2_DIV — Divide clk_utmi_otg2 by (div_con + 1).
  [7] CLK_GMAC_50M_CRU_I_SEL — clk_gmac_50m_cru_i clock mux.
    0=CLK_GPLL_MUX; 1=CLK_CPLL_MUX
  [6:0] CLK_GMAC_50M_CRU_I_DIV — Divide clk_gmac_50m_cru_i by (div_con + 1).
0x454 CLKSEL_CON85 — Internal clock select and division register 85
  [11:6] CLK_GMAC1_TX_125M_O_DIV — Divide clk_gmac1_tx_125m_o by (div_con + 1).
  [5:0] CLK_GMAC0_TX_125M_O_DIV — Divide clk_gmac0_tx_125m_o by (div_con + 1).
0x464 CLKSEL_CON89 — Internal clock select and division register 89
  [15:14] ACLK_RKVDEC_CCU_SEL — aclk_rkvdec_ccu clock mux.
    values as CLKSEL_CON67.CLK_ISP1_CORE_SEL
  [13:9] ACLK_RKVDEC_CCU_DIV — Divide aclk_rkvdec_ccu by (div_con + 1).
  [8:7] ACLK_RKVDEC0_ROOT_SEL — aclk_rkvdec0_root clock mux.
    values as CLKSEL_CON67.CLK_ISP1_CORE_SEL
  [6:2] ACLK_RKVDEC0_ROOT_DIV — Divide aclk_rkvdec0_root by (div_con + 1).
  [1:0] HCLK_RKVDEC0_ROOT_SEL — hclk_rkvdec0_root clock mux.
    values as CLKSEL_CON09.ACLK_TOP_S200_ROOT_SEL
0x468 CLKSEL_CON90 — Internal clock select and division register 90
  [12:11] CLK_RKVDEC0_HEVC_CA_SEL — clk_rkvdec0_hevc_ca clock mux.
    0=CLK_GPLL_MUX; 1=CLK_CPLL_MUX; 2=CLK_NPLL_MUX; 3=CLK_MATRIX_1000M_SRC
  [10:6] CLK_RKVDEC0_HEVC_CA_DIV — Divide clk_rkvdec0_hevc_ca by (div_con + 1).
  [5] CLK_RKVDEC0_CA_SEL — clk_rkvdec0_ca clock mux.
    0=CLK_GPLL_MUX; 1=CLK_CPLL_MUX
  [4:0] CLK_RKVDEC0_CA_DIV — Divide clk_rkvdec0_ca by (div_con + 1).
0x46C CLKSEL_CON91 — Internal clock select and division register 91
  [5] CLK_RKVDEC0_CORE_SEL — clk_rkvdec0_core clock mux.
    0=CLK_GPLL_MUX; 1=CLK_CPLL_MUX
  [4:0] CLK_RKVDEC0_CORE_DIV — Divide clk_rkvdec0_core by (div_con + 1).
0x474 CLKSEL_CON93 — Internal clock select and division register 93
  [14] CLK_RKVDEC1_CA_SEL — clk_rkvdec1_ca clock mux.
    0=CLK_GPLL_MUX; 1=CLK_CPLL_MUX
  [13:9] CLK_RKVDEC1_CA_DIV — Divide clk_rkvdec1_ca by (div_con + 1).
  [8:7] ACLK_RKVDEC1_ROOT_SEL — aclk_rkvdec1_root clock mux.
    0=CLK_GPLL_MUX; 1=CLK_CPLL_MUX; 2=CLK_AUPLL_MUX; 3=CLK_NPLL_MUX
  [6:2] ACLK_RKVDEC1_ROOT_DIV — Divide aclk_rkvdec1_root by (div_con + 1).
  [1:0] HCLK_RKVDEC1_ROOT_SEL — hclk_rkvdec1_root clock mux.
    values as CLKSEL_CON09.ACLK_TOP_S200_ROOT_SEL
0x478 CLKSEL_CON94 — Internal clock select and division register 94
  [12] CLK_RKVDEC1_CORE_SEL — clk_rkvdec1_core clock mux.
    0=CLK_GPLL_MUX; 1=CLK_CPLL_MUX
  [11:7] CLK_RKVDEC1_CORE_DIV — Divide clk_rkvdec1_core by (div_con + 1).
  [6:5] CLK_RKVDEC1_HEVC_CA_SEL — clk_rkvdec1_hevc_ca clock mux.
    values as CLKSEL_CON90.CLK_RKVDEC0_HEVC_CA_SEL
  [4:0] CLK_RKVDEC1_HEVC_CA_DIV — Divide clk_rkvdec1_hevc_ca by (div_con + 1).
0x480 CLKSEL_CON96 — Internal clock select and division register 96
  [7:6] HCLK_USB_ROOT_SEL — hclk_usb_root clock mux.
    0=CLK_MATRIX_150M_SRC; 1=CLK_MATRIX_100M_SRC; 2=CLK_MATRIX_50M_SRC; 3=XIN_OSC0_FUNC
  [5] ACLK_USB_ROOT_SEL — aclk_usb_root clock mux.
    0=CLK_GPLL_MUX; 1=CLK_CPLL_MUX
  [4:0] ACLK_USB_ROOT_DIV — Divide aclk_usb_root by (div_con + 1).
